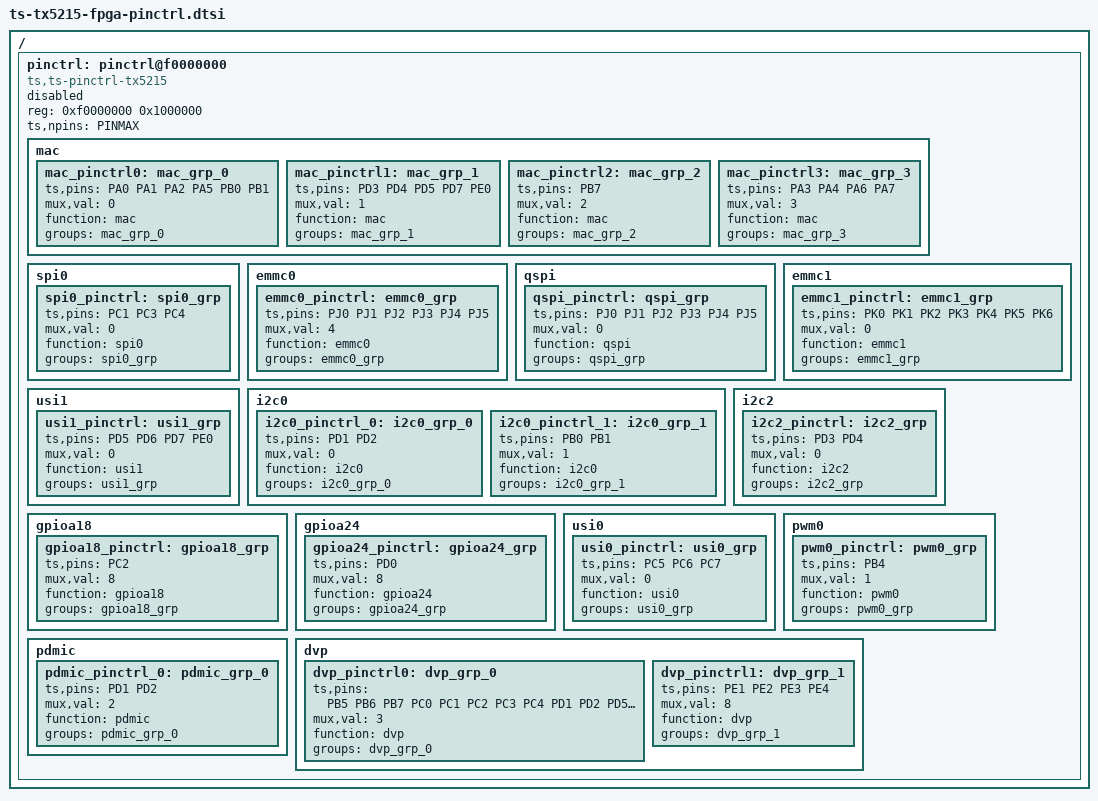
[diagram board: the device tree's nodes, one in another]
/*
 * dts file for tsingmicro tx5215
 *
 * Copyright 2022 Tsingmicro, Inc.
 *
 * This program is free software; you can redistribute it and/or
 * modify it under the terms of the GNU General Public License as
 * published by the Free Software Foundation; either version 2 of
 * the License, or (at your option) any later version.
 */

#include <dt-bindings/pinctrl/pinctrl-ts-tx5215.h>
/ {
		pinctrl: pinctrl@f0000000 {
			compatible = "ts,ts-pinctrl-tx5215";
			status = "disabled";
			reg = <0xf0000000 0x1000000>;
			ts,npins = <PINMAX>;

			mac {
				mac_pinctrl0: mac_grp_0 {
					ts,pins = <PA0 PA1 PA2 PA5 PB0 PB1>;
					mux,val = <0>;
					function = "mac";
					groups = "mac_grp_0";
				};
				mac_pinctrl1: mac_grp_1 {
					ts,pins = <PD3 PD4 PD5 PD7 PE0>;
					mux,val = <1>;
					function = "mac";
					groups = "mac_grp_1";
				};
				mac_pinctrl2: mac_grp_2 {
					ts,pins = <PB7>;
					mux,val = <2>;
					function = "mac";
					groups = "mac_grp_2";
				};
				mac_pinctrl3: mac_grp_3 {
					ts,pins = <PA3 PA4 PA6 PA7>;
					mux,val = <3>;
					function = "mac";
					groups = "mac_grp_3";
				};
			};

			spi0 {
				spi0_pinctrl: spi0_grp {
					ts,pins = <PC1 PC3 PC4>;
					mux,val = <0>;
					function = "spi0";
					groups = "spi0_grp";
				};
			};

			emmc0 {
				emmc0_pinctrl: emmc0_grp {
					ts,pins = <PJ0 PJ1 PJ2 PJ3 PJ4 PJ5>;
					mux,val = <4>;
					function = "emmc0";
					groups = "emmc0_grp";
				};
			};

			qspi {
				qspi_pinctrl: qspi_grp {
					ts,pins = <PJ0 PJ1 PJ2 PJ3 PJ4 PJ5>;
					mux,val = <0>;
					function = "qspi";
					groups = "qspi_grp";
				};
			};

			emmc1 {
				emmc1_pinctrl: emmc1_grp {
					ts,pins = <PK0 PK1 PK2 PK3 PK4 PK5 PK6>;
					mux,val = <0>;
					function = "emmc1";
					groups = "emmc1_grp";
				};
			};

			usi1 {
				usi1_pinctrl: usi1_grp {
					ts,pins = <PD5 PD6 PD7 PE0>;
					mux,val = <0>;
					function = "usi1";
					groups = "usi1_grp";
				};
			};

			i2c0 {
				i2c0_pinctrl_0: i2c0_grp_0 {
					ts,pins = <PD1 PD2>;
					mux,val = <0>;
					function = "i2c0";
					groups = "i2c0_grp_0";
				};
				i2c0_pinctrl_1: i2c0_grp_1 {
					ts,pins = <PB0 PB1>;
					mux,val = <1>;
					function = "i2c0";
					groups = "i2c0_grp_1";
				};
			};

			i2c2 {
				i2c2_pinctrl: i2c2_grp {
					ts,pins = <PD3 PD4>;
					mux,val = <0>;
					function = "i2c2";
					groups = "i2c2_grp";
				};
			};

			gpioa18 {
				gpioa18_pinctrl: gpioa18_grp {
					ts,pins = <PC2>;
					mux,val = <8>;
					function = "gpioa18";
					groups = "gpioa18_grp";
				};
			};

			gpioa24 {
				gpioa24_pinctrl: gpioa24_grp {
					ts,pins = <PD0>;
					mux,val = <8>;
					function = "gpioa24";
					groups = "gpioa24_grp";
				};
			};

			usi0 {
				usi0_pinctrl: usi0_grp {
					ts,pins = <PC5 PC6 PC7>;
					mux,val = <0>;
					function = "usi0";
					groups = "usi0_grp";
				};
			};

			pwm0{
				pwm0_pinctrl:pwm0_grp{
					ts,pins = <PB4>;
					mux,val = <1>;
					function = "pwm0";
					groups = "pwm0_grp";
				};
			};

			pdmic {
				pdmic_pinctrl_0: pdmic_grp_0 {
					ts,pins = <PD1 PD2>;
					mux,val = <2>;
					function = "pdmic";
					groups = "pdmic_grp_0";
				};
			};

			dvp {
				dvp_pinctrl0: dvp_grp_0 {
					ts,pins = <PB5 PB6 PB7 PC0 PC1 PC2 PC3 PC4 PD1 PD2 PD5 PD6 PD7 PE0>;
					mux,val = <3>;
					function = "dvp";
					groups = "dvp_grp_0";
				};
				dvp_pinctrl1: dvp_grp_1 {
					ts,pins = <PE1 PE2 PE3 PE4>;
					mux,val = <8>;
					function = "dvp";
					groups = "dvp_grp_1";
				};
			};
		};
};

